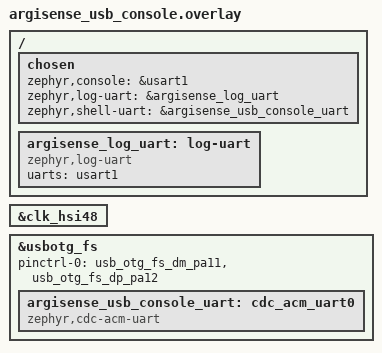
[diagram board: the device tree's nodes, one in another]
/*
 * SPDX-License-Identifier: Apache-2.0
 *
 * Keep Zephyr console/logs on USART1 for bring-up, and route the shell to
 * the board USB-C connector through USB CDC ACM on STM32U575 USB FS pins
 * PA11/PA12.
 */

/ {
	chosen {
		zephyr,console = &usart1;
		zephyr,log-uart = &argisense_log_uart;
		zephyr,shell-uart = &argisense_usb_console_uart;
	};

	argisense_log_uart: log-uart {
		compatible = "zephyr,log-uart";
		uarts = <&usart1>;
	};
};

&clk_hsi48 {
	status = "okay";
};

zephyr_udc0: &usbotg_fs {
	pinctrl-0 = <&usb_otg_fs_dm_pa11 &usb_otg_fs_dp_pa12>;
	pinctrl-names = "default";
	status = "okay";

	argisense_usb_console_uart: cdc_acm_uart0 {
		compatible = "zephyr,cdc-acm-uart";
	};
};
